# apollo3p register map
Vendor: Ambiq Micro; Series: Apollo; File version: 1.0
CPU: CM4 r1p0, little endian, MPU, FPU, I-cache, D-cache, VTOR, ITCM, DTCM, 3 interrupt priority bits, 0 interrupts
Registers are 32-bit, read-write, reset 0x0 unless marked. A register's access mark holds for its fields unless they carry their own. Offsets are from the block's base; [hi:lo] are bit positions; lines under a group give offsets from that group; {n}, {i} and the like mark numbered series; 'fields as' and 'values as' point back to an identical list.

## PWRCTRL — PWR Controller Register Bank
Base 0x40021000
0x00 SUPPLYSRC — This register controls the enable for BLE BUCK.
  [0] BLEBUCKEN — Enables and Selects the BLE Buck as the supply for the BLE power domain or for Burst LDO. It takes the initial value from Customer INFO space. Buck will be powered up only if there is an active request for BLEH domain or Burst mode and appropriate feature is allowed.
    1=EN (Enable the BLE Buck.); 0=DIS (Disable the BLE Buck.)
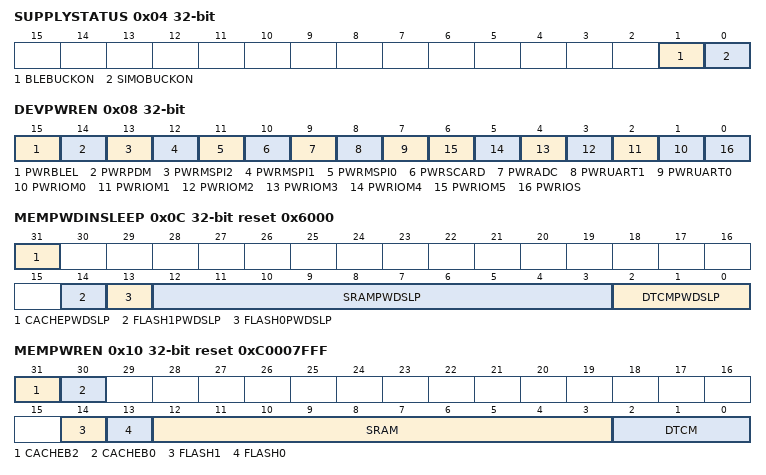
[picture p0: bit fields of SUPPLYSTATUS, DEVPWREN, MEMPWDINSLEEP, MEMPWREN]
0x04 SUPPLYSTATUS — Provides an indicator for the BLE BUCK and SIMO BUCK status. Once the SIMO BUCK is powered up MEM and CORE LDOs are disabled.
  [1] BLEBUCKON — Indicates whether the BLE (if supported) domain and burst (if supported) domain is supplied from the LDO or the Buck. Buck will be powered up only if there is an active request for BLEH domain or Burst mode and appropriate feature is allowed.
    0=LDO (Indicates the the LDO is supplying the BLE/Burst power domain); 1=BUCK (Indicates the the Buck is supplying the BLE/Burst power domain)
  [0] SIMOBUCKON — Indicates whether the Core/Mem low-voltage domains are supplied from the LDO or the Buck.
    0=OFF (Indicates the the SIMO Buck is OFF.); 1=ON (Indicates the the SIMO Buck is ON.)
0x08 DEVPWREN — This enables various peripherals power domains.
  [15] PWRBLEL — Power up BLE controller
    1=EN (Power up BLE controller); 0=DIS (Power down BLE controller)
  [14] PWRPDM — Power up PDM block
    1=EN (Power up PDM); 0=DIS (Power down PDM)
  [13] PWRMSPI2 — Power up MSPI2 Controller
    1=EN (Power up MSPI2); 0=DIS (Power down MSPI2)
  [12] PWRMSPI1 — Power up MSPI1 Controller
    1=EN (Power up MSPI1); 0=DIS (Power down MSPI1)
  [11] PWRMSPI0 — Power up MSPI0 Controller
    1=EN (Power up MSPI0); 0=DIS (Power down MSPI0)
  [10] PWRSCARD — Power up SCARD Controller
    1=EN (Power up SCARD); 0=DIS (Power down SCARD)
  [9] PWRADC — Power up ADC Digital Controller
    1=EN (Power up ADC); 0=DIS (Power Down ADC)
  [8] PWRUART1 — Power up UART Controller 1
    1=EN (Power up UART 1); 0=DIS (Power down UART 1)
  [7] PWRUART0 — Power up UART Controller 0
    1=EN (Power up UART 0); 0=DIS (Power down UART 0)
  [n+1] PWRIOM{n} (n=0..5) — Power up IO Master {n}
    1=EN (Power up IO Master {n}); 0=DIS (Power down IO Master {n})
  [0] PWRIOS — Power up IO Slave
    1=EN (Power up IO slave); 0=DIS (Power down IO slave)
0x0C MEMPWDINSLEEP reset 0x6000 — This controls the power down of the SRAM banks in deep sleep mode. If this is set, then the power for that SRAM bank will be gated when the core goes into deep sleep. Upon wake, the data within the SRAMs will be erased. If this is not set, retention voltage will be applied to the SRAM bank when the core goes into deep sleep. Upon wake, the data within the SRAMs are retained. Do not set this if the SRAM bank is used as the target for DMA transfer while CPU in deep sleep.
  [31] CACHEPWDSLP — power down cache in deep sleep
    1=EN (Power down cache in deep sleep); 0=DIS (Retain cache in deep sleep)
  [14] FLASH1PWDSLP — Power-down FLASH1 in deep sleep
    1=EN (FLASH1 is powered down during deep sleep); 0=DIS (FLASH1 is kept powered on during deep sleep)
  [13] FLASH0PWDSLP — Power-down FLASH0 in deep sleep
    1=EN (FLASH0 is powered down during deep sleep); 0=DIS (FLASH0 is kept powered on during deep sleep)
  [12:3] SRAMPWDSLP — Selects which SRAM banks are powered down in deep sleep mode, causing the contents of the bank to be lost.
    0=NONE (All banks retained); 1=GROUP0 (SRAM GROUP0 powered down (64KB-128KB)); 2=GROUP1 (SRAM GROUP1 powered down (128KB-192KB)); 4=GROUP2 (SRAM GROUP2 powered down (192KB-256KB)); 8=GROUP3 (SRAM GROUP3 powered down (256KB-320KB)); 16=GROUP4 (SRAM GROUP4 powered down (320KB-384KB)); 32=GROUP5 (SRAM GROUP5 powered down (384KB-448KB)); 64=GROUP6 (SRAM GROUP6 powered down (448KB-512KB)); 128=GROUP7 (SRAM GROUP7 powered down (512KB-576KB)); 0x100=GROUP8 (SRAM GROUP8 powered down (576KB-672KB)); 0x200=GROUP9 (SRAM GROUP9 powered down (672KB-768KB)); 3=SRAM128K (Power-down lower 128k SRAM (64KB-192KB)); 15=SRAM256K (Power-down lower 256k SRAM (64KB-320KB)); 0x3FE=ALLBUTLOWER64K (All SRAM banks but lower 64k powered down.); 0x3FC=ALLBUTLOWER128K (All banks but lower 128k powered down.); 0x3F0=ALLBUTLOWER256K (All banks but lower 256k powered down.); 0x3FF=ALL (All banks powered down.)
  [2:0] DTCMPWDSLP — power down DTCM in deep sleep
    0=NONE (All DTCM retained); 1=GROUP0DTCM0 (Group0_DTCM0 powered down in deep sleep (0KB-8KB)); 2=GROUP0DTCM1 (Group0_DTCM1 powered down in deep sleep (8KB-32KB)); 3=GROUP0 (Both DTCMs in group0 are powered down in deep sleep (0KB-32KB)); 6=ALLBUTGROUP0DTCM0 (Group1 and Group0_DTCM1 are powered down in deep sleep (8KB-64KB)); 4=GROUP1 (Group1 DTCM powered down in deep sleep (32KB-64KB)); 7=ALL (All DTCMs powered down in deep sleep (0KB-64KB))
0x10 MEMPWREN reset 0xC0007FFF — This register enables the individual banks for the memories. When set, power will be enabled to the banks. This register works in conjunction with the MEMPWDINSLEEP register. When this register is set, then the MEMPWRINSLEEP register will determine whether power is enabled to the SRAMs in deep sleep. If this register is not set, then power will always be disabled to the memory bank.
  [31] CACHEB2 — Power up Cache Bank 2. This works in conjunction with Cache enable from flash_cache module. To power up cache bank 2, cache has to be enabled and this bit has to be set.
    1=EN (Power up Cache Bank 2); 0=DIS (Power down Cache Bank 2)
  [30] CACHEB0 — Power up Cache Bank 0. This works in conjunction with Cache enable from flash_cache module. To power up cache bank 0, cache has to be enabled and this bit has to be set.
    1=EN (Power up Cache Bank 0); 0=DIS (Power down Cache Bank 0)
  [14] FLASH1 — Power up FLASH group 1 (1MB-2MB)
    1=EN (Power up FLASH group 1 (1MB-2MB)); 0=DIS (Power down FLASH group 1 (1MB-2MB))
  [13] FLASH0 — Power up FLASH group 0 (0MB-1MB)
    1=EN (Power up FLASH group 0 (0MB-1MB)); 0=DIS (Power down FLASH group 0 (0MB-1MB))
  [12:3] SRAM — Power up SRAM groups
    0=NONE (Do not power ON any of the SRAM banks); 1=GROUP0 (Power ON only SRAM 64KB group0 (addr: 0x10010000 - 0x1001FFFF)); 2=GROUP1 (Power ON only SRAM 64KB group1 (addr: 0x10020000 - 0x1002FFFF)); 4=GROUP2 (Power ON only SRAM 64KB group2 (addr: 0x10030000 - 0x1003FFFF)); 8=GROUP3 (Power ON only SRAM 64KB group3 (addr: 0x10040000 - 0x1004FFFF)); 16=GROUP4 (Power ON only SRAM 64KB group4 (addr: 0x10050000 - 0x1005FFFF)); 32=GROUP5 (Power ON only SRAM 64KB group5 (addr: 0x10060000 - 0x1006FFFF)); 64=GROUP6 (Power ON only SRAM 64KB group6 (addr: 0x10070000 - 0x1007FFFF)); 128=GROUP7 (Power ON only SRAM 64KB group7 (addr: 0x10080000 - 0x1008FFFF)); 0x100=GROUP8 (Power ON only SRAM 96KB group8 (addr: 0x10090000 - 0x100A7FFF)); 0x200=GROUP9 (Power ON only SRAM 96KB group9 (addr: 0x100A8000 - 0x100BFFFF)); 3=SRAM128K (Power ON only lower 128k (addr: 0x10010000 - 0x1002FFFF)); 15=SRAM256K (Power ON only lower 256k (addr: 0x10010000 - 0x1004FFFF)); 255=SRAM512K (Power ON only lower 512k (addr: 0x10010000 - 0x1008FFFF)); 0x3FF=ALL (All SRAM banks (704K) powered ON (addr: 0x10010000 - 0x100BFFFF))
  [2:0] DTCM — Power up DTCM
    0=NONE (Do not enable power to any DTCMs); 1=GROUP0DTCM0 (Power ON only 8KB GROUP0_DTCM0 (0 - 8KB, addr: 0x10000000 - 0x10001FFF)); 2=GROUP0DTCM1 (Power ON only 24KB GROUP0_DTCM1 (8KB - 32KB, addr: 0x10002000 - 0x10007FFF)); 3=GROUP0 (Power ON only DTCMs in 32KB group0 (0 - 32KB, addr: 0x10000000 - 0x10007FFF)); 4=GROUP1 (Power ON only DTCMs in 32KB group1 (32KB - 64KB, addr: 0x10008000 - 0x1000FFFF)); 7=ALL (Power ON all DTCMs (0 - 64KB, addr: 0x10000000 - 0x1000FFFF))
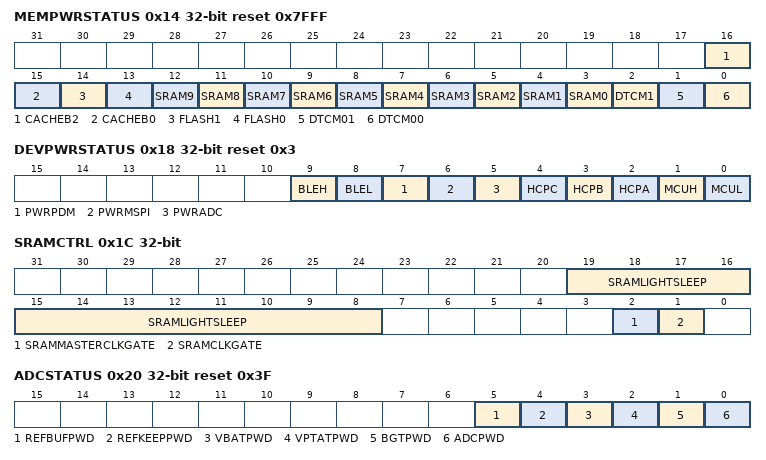
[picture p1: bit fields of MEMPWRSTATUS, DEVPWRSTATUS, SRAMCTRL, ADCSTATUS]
0x14 MEMPWRSTATUS reset 0x7FFF — It provides the power status for all the memory banks including- caches, FLASH (0 and 1) and all the SRAM groups. The status here should reflect the enable provided by the MEMPWREN register. There may be a lag time between setting the bits in MEMPWREN register and MEMPWRSTATUS register, due to the need to cycle the power gate and isolation sequences to the memory banks.
  [16] CACHEB2 — This bit is 1 if power is supplied to Cache Bank 2
  [15] CACHEB0 — This bit is 1 if power is supplied to Cache Bank 0
  [14] FLASH1 — This bit is 1 if power is supplied to FLASH group 1
  [13] FLASH0 — This bit is 1 if power is supplied to FLASH group 0
  [n+3] SRAM{n} (n=0..9) — This bit is 1 if power is supplied to SRAM GROUP{n}
  [2] DTCM1 — This bit is 1 if power is supplied to DTCM GROUP1
  [1] DTCM01 — This bit is 1 if power is supplied to DTCM GROUP0_1
  [0] DTCM00 — This bit is 1 if power is supplied to DTCM GROUP0_0
0x18 DEVPWRSTATUS reset 0x3 — This provides the power status for the peripheral devices- BLEL, PDM, PDM, MSPI2-0, SCARD, ADC, UART0 and 1, IOM5 to 0, IOSLAVE and MCUL (DMA and Fabrics) and MCUH (ARM core). The status here should reflect the enable provided by the DEVPWREN register. There may be a lag time between setting the bits in DEVPWREN register and DEVPWRSTATUS register, due to the need to cycle the power gate, isolation and reset sequences to the device power domains.
  [9] BLEH — This bit is 1 if power is supplied to BLEH
  [8] BLEL — This bit is 1 if power is supplied to BLEL
  [7] PWRPDM — This bit is 1 if power is supplied to PDM
  [6] PWRMSPI — This bit is 1 if power is supplied to MSPI
  [5] PWRADC — This bit is 1 if power is supplied to ADC
  [4] HCPC — This bit is 1 if power is supplied to HCPC domain (IO MASTER4, 5, 6)
  [3] HCPB — This bit is 1 if power is supplied to HCPB domain (IO MASTER 0, 1, 2)
  [2] HCPA — This bit is 1 if power is supplied to HCPA domain (IO SLAVE, UART0, UART1, SCARD)
  [1] MCUH — This bit is 1 if power is supplied to MCUH
  [0] MCUL — This bit is 1 if power is supplied to MCUL
0x1C SRAMCTRL — This register provides additional fine-tune power management controls for the SRAMs and the SRAM controller. This includes enabling light sleep for the SRAM and TCM banks, and clock gating for reduced dynamic power.
  [19:8] SRAMLIGHTSLEEP — Light Sleep enable for each TCM/SRAM bank. When 1, corresponding bank will be put into light sleep. For optimal power, banks should be put into light sleep while the system is active but the bank has minimal or no accesses.
    255=ALL (Enable LIGHT SLEEP for ALL SRAMs); 0=DIS (Disables LIGHT SLEEP for ALL SRAMs)
  [2] SRAMMASTERCLKGATE — This bit is 1 when the master clock gate is enabled (top-level clock gate for entire SRAM block)
    1=EN (Enable Master SRAM Clock Gate); 0=DIS (Disables Master SRAM Clock Gating)
  [1] SRAMCLKGATE — This bit is 1 if clock gating is allowed for individual system SRAMs
    1=EN (Enable Individual SRAM Clock Gating); 0=DIS (Disables Individual SRAM Clock Gating)
0x20 ADCSTATUS reset 0x3F — This provides the power status for various blocks within the ADC. These status comes directly from the ADC module and is captured through this interface.
  [5] REFBUFPWD — This bit indicates that the ADC REFBUF is powered down
  [4] REFKEEPPWD — This bit indicates that the ADC REFKEEP is powered down
  [3] VBATPWD — This bit indicates that the ADC VBAT resistor divider is powered down
  [2] VPTATPWD — This bit indicates that the ADC temperature sensor input buffer is powered down
  [1] BGTPWD — This bit indicates that the ADC Band Gap is powered down
  [0] ADCPWD — This bit indicates that the ADC is powered down
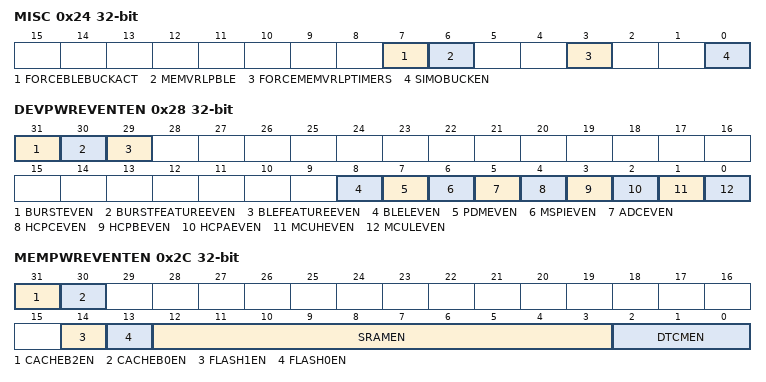
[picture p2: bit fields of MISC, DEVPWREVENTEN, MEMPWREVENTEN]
0x24 MISC — This register includes additional debug control bits. This is an internal Ambiq-only register. Customers should not attempt to change this or else functionality cannot be guaranteed.
  [7] FORCEBLEBUCKACT — Control Bit to enable BLE Buck to be in active state when BLE Buck is enabled. Default behavior is to be in active only when Burst or BLEH power on are requested.
  [6] MEMVRLPBLE — Control Bit to let Mem VR go to lp mode in deep sleep even when BLEL or BLEH is powered on given none of the other domains require it.
    1=EN (Mem VR can go to lp mode even when BLE is powered on.); 0=DIS (Mem VR will stay in active mode when BLE is powered on.)
  [3] FORCEMEMVRLPTIMERS — Control Bit to force Mem VR to LP mode in deep sleep even when hfrc based ctimer or stimer is running.
  [0] SIMOBUCKEN — Enables and Selects the SIMO Buck as the supply for the low-voltage power domain. It takes the initial value from the bit set in Customer INFO space.
    1=EN (Enable the SIMO Buck); 0=DIS (Disable the SIMO Buck)
0x28 DEVPWREVENTEN — This register controls which feature trigger will result in an event to the CPU. It includes all the power on status for the core domains, as well as the Burst event. If any bits are set, then if the domain is turned on, it will result in an event to the ARM core.
  [31] BURSTEVEN — Control BURST status event
    1=EN (Enable BURST status event); 0=DIS (Disable BURST status event)
  [30] BURSTFEATUREEVEN — Control BURSTFEATURE status event
    1=EN (Enable BURSTFEATURE status event); 0=DIS (Disable BURSTFEATURE status event)
  [29] BLEFEATUREEVEN — Control BLEFEATURE status event
    1=EN (Enable BLEFEATURE status event); 0=DIS (Disable BLEFEATURE status event)
  [8] BLELEVEN — Control BLE power-on status event
    1=EN (Enable BLE power-on status event); 0=DIS (Disable BLE power-on status event)
  [7] PDMEVEN — Control PDM power-on status event
    1=EN (Enable PDM power-on status event); 0=DIS (Disable PDM power-on status event)
  [6] MSPIEVEN — Control MSPI power-on status event
    1=EN (Enable MSPI power-on status event); 0=DIS (Disable MSPI power-on status event)
  [5] ADCEVEN — Control ADC power-on status event
    1=EN (Enable ADC power-on status event); 0=DIS (Disable ADC power-on status event)
  [4] HCPCEVEN — Control HCPC power-on status event
    1=EN (Enable HCPC power-on status event); 0=DIS (Disable HCPC power-on status event)
  [3] HCPBEVEN — Control HCPB power-on status event
    1=EN (Enable HCPB power-on status event); 0=DIS (Disable HCPB power-on status event)
  [2] HCPAEVEN — Control HCPA power-on status event
    1=EN (Enable HCPA power-on status event); 0=DIS (Disable HCPA power-on status event)
  [1] MCUHEVEN — Control MCUH power-on status event
    1=EN (Enable MCHU power-on status event); 0=DIS (Disable MCUH power-on status event)
  [0] MCULEVEN — Control MCUL power-on status event
    1=EN (Enable MCUL power-on status event); 0=DIS (Disable MCUL power-on status event)
0x2C MEMPWREVENTEN — This register controls which power enable for the memories will result in an event to the CPU. It includes all the power on status for the memory domains. If any bits are set, then if the domain is turned on, it will result in an event to the ARM core.
  [31] CACHEB2EN — Control CACHEB2 power-on status event
    1=EN (Enable CACHE BANK 2 status event); 0=DIS (Disable CACHE BANK 2 status event)
  [30] CACHEB0EN — Control CACHE BANK 0 power-on status event
    1=EN (Enable CACHE BANK 0 status event); 0=DIS (Disable CACHE BANK 0 status event)
  [14] FLASH1EN — Control FLASH power-on status event
    1=EN (Enable FLASH status event); 0=DIS (Disables FLASH status event)
  [13] FLASH0EN — Control FLASH power-on status event
    values as FLASH1EN
  [12:3] SRAMEN — Control SRAM power-on status event
    0=NONE (Disable SRAM power-on status event); 1=GROUP0EN (Enable SRAM group0 (0KB-32KB) power on status event); 2=GROUP1EN (Enable SRAM group1 (32KB-64KB) power on status event); 4=GROUP2EN (Enable SRAM group2 (64KB-96KB) power on status event); 8=GROUP3EN (Enable SRAM group3 (96KB-128KB) power on status event); 16=GROUP4EN (Enable SRAM group4 (128KB-160KB) power on status event); 32=GROUP5EN (Enable SRAM group5 (160KB-192KB) power on status event); 64=GROUP6EN (Enable SRAM group6 (192KB-224KB) power on status event); 128=GROUP7EN (Enable SRAM group7 (224KB-256KB) power on status event); 0x100=GROUP8EN (Enable SRAM group8 (256KB-288KB) power on status event); 0x200=GROUP9EN (Enable SRAM group9 (288KB-320KB) power on status event)
  [2:0] DTCMEN — Enable DTCM power-on status event
    0=NONE (Do not enable DTCM power-on status event); 1=GROUP0DTCM0EN (Enable GROUP0_DTCM0 power on status event); 2=GROUP0DTCM1EN (Enable GROUP0_DTCM1 power on status event); 3=GROUP0EN (Enable DTCMs in group0 power on status event); 4=GROUP1EN (Enable DTCMs in group1 power on status event); 7=ALL (Enable all DTCM power on status event)
